# PIC32MX170F256D register map
Registers are 32-bit, access not given, reset 0x0 unless marked. A register's access mark holds for its fields unless they carry their own. Offsets are from the block's base; [hi:lo] are bit positions; {n}, {i} and the like mark numbered series; 'fields as' and 'values as' point back to an identical list.

## DMAC3 — DMAC3 peripheral
Base 0xBF8832A0
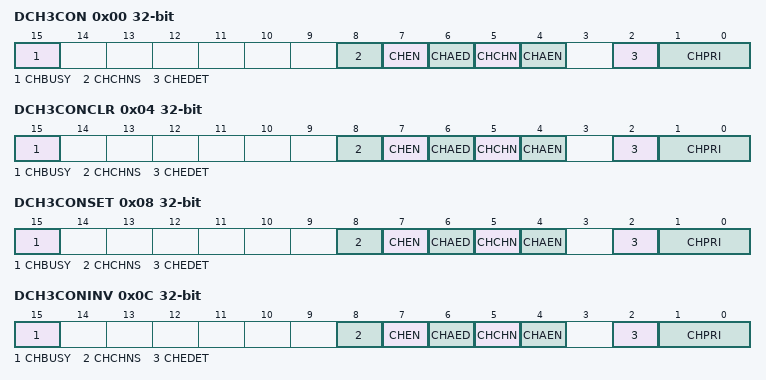
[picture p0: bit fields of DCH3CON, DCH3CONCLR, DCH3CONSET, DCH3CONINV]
0x00 DCH3CON
  [15] CHBUSY, [8] CHCHNS, [7] CHEN, [6] CHAED, [5] CHCHN, [4] CHAEN, [2] CHEDET, [1:0] CHPRI
0x04 DCH3CONCLR
  fields as DCH3CON
0x08 DCH3CONSET
  fields as DCH3CON
0x0C DCH3CONINV
  fields as DCH3CON
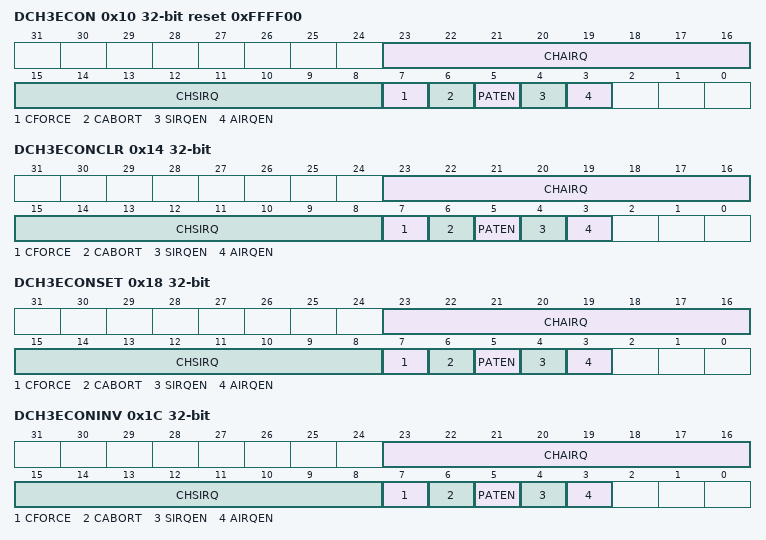
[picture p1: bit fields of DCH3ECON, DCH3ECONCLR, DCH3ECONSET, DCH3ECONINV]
0x10 DCH3ECON reset 0xFFFF00
  [23:16] CHAIRQ, [15:8] CHSIRQ, [7] CFORCE, [6] CABORT, [5] PATEN, [4] SIRQEN, [3] AIRQEN
0x14 DCH3ECONCLR
  fields as DCH3ECON
0x18 DCH3ECONSET
  fields as DCH3ECON
0x1C DCH3ECONINV
  fields as DCH3ECON
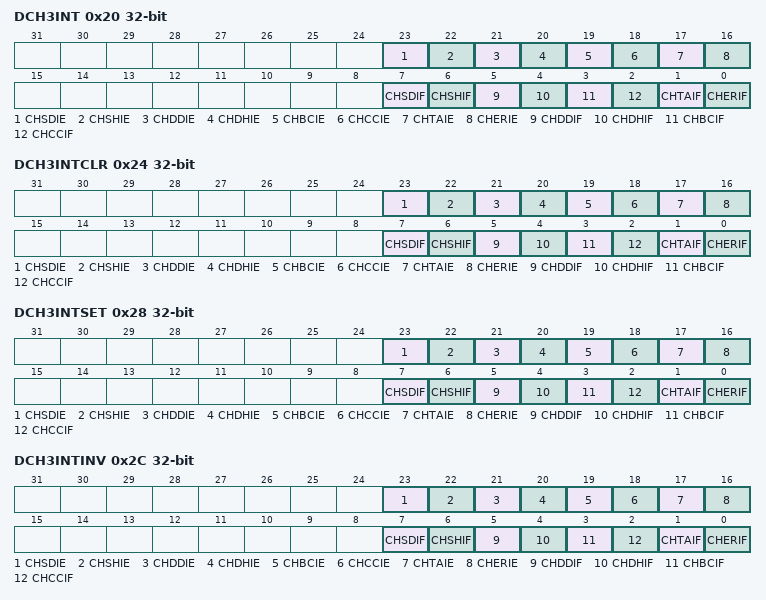
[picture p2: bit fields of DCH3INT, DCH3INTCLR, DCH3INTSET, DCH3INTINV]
0x20 DCH3INT
  [23] CHSDIE, [22] CHSHIE, [21] CHDDIE, [20] CHDHIE, [19] CHBCIE, [18] CHCCIE, [17] CHTAIE, [16] CHERIE, [7] CHSDIF, [6] CHSHIF, [5] CHDDIF, [4] CHDHIF, [3] CHBCIF, [2] CHCCIF, [1] CHTAIF, [0] CHERIF
0x24 DCH3INTCLR
  fields as DCH3INT
0x28 DCH3INTSET
  fields as DCH3INT
0x2C DCH3INTINV
  fields as DCH3INT
0x30 DCH3SSA
0x34 DCH3SSACLR
  [31:0] DCH3SSA
0x38 DCH3SSASET
  [31:0] DCH3SSA
0x3C DCH3SSAINV
  [31:0] DCH3SSA
0x40 DCH3DSA
0x44 DCH3DSACLR
  [31:0] DCH3DSA
0x48 DCH3DSASET
  [31:0] DCH3DSA
0x4C DCH3DSAINV
  [31:0] DCH3DSA
0x50 DCH3SSIZ
  [15:0] CHSSIZ
0x54 DCH3SSIZCLR
  [15:0] CHSSIZ
0x58 DCH3SSIZSET
  [15:0] CHSSIZ
0x5C DCH3SSIZINV
  [15:0] CHSSIZ
0x60 DCH3DSIZ
  [15:0] CHDSIZ
0x64 DCH3DSIZCLR
  [15:0] CHDSIZ
0x68 DCH3DSIZSET
  [15:0] CHDSIZ
0x6C DCH3DSIZINV
  [15:0] CHDSIZ
0x70 DCH3SPTR
  [15:0] CHSPTR
0x74 DCH3SPTRCLR
  [15:0] CHSPTR
0x78 DCH3SPTRSET
  [15:0] CHSPTR
0x7C DCH3SPTRINV
  [15:0] CHSPTR
0x80 DCH3DPTR
  [15:0] CHDPTR
0x84 DCH3DPTRCLR
  [15:0] CHDPTR
0x88 DCH3DPTRSET
  [15:0] CHDPTR
0x8C DCH3DPTRINV
  [15:0] CHDPTR
0x90 DCH3CSIZ
  [15:0] CHCSIZ
0x94 DCH3CSIZCLR
  [15:0] CHCSIZ
0x98 DCH3CSIZSET
  [15:0] CHCSIZ
0x9C DCH3CSIZINV
  [15:0] CHCSIZ
0xA0 DCH3CPTR
  [15:0] CHCPTR
0xA4 DCH3CPTRCLR
  [15:0] CHCPTR
0xA8 DCH3CPTRSET
  [15:0] CHCPTR
0xAC DCH3CPTRINV
  [15:0] CHCPTR
0xB0 DCH3DAT
  [7:0] DCHPDAT
0xB4 DCH3DATCLR
  [7:0] DCHPDAT
0xB8 DCH3DATSET
  [7:0] DCHPDAT
0xBC DCH3DATINV
  [7:0] DCHPDAT

## PORTA — PORTA peripheral
Base 0xBF886000
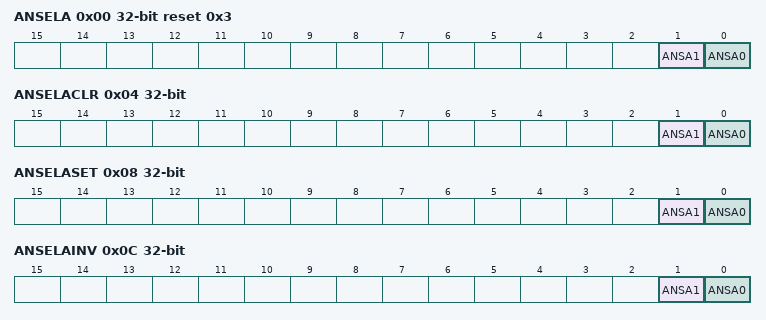
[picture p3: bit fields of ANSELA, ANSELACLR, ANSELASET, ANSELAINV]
0x00 ANSELA reset 0x3
  [1] ANSA1, [0] ANSA0
0x04 ANSELACLR
  [1] ANSA1, [0] ANSA0
0x08 ANSELASET
  [1] ANSA1, [0] ANSA0
0x0C ANSELAINV
  [1] ANSA1, [0] ANSA0
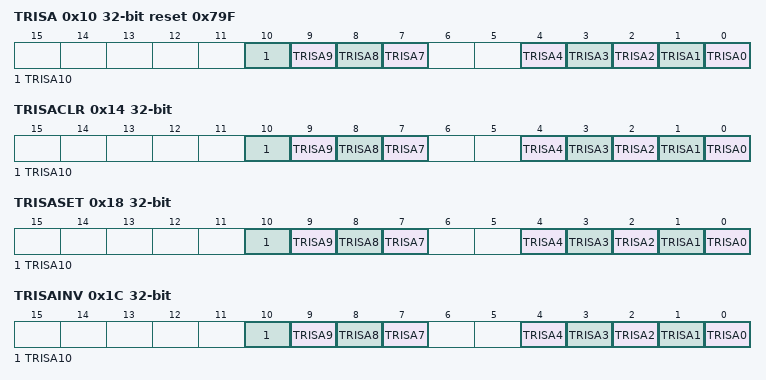
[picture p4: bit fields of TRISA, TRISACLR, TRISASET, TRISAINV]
0x10 TRISA reset 0x79F
  [n] TRISA{n} (n=7..10), [n] TRISA{n} (n=0..4)
0x14 TRISACLR
  [n] TRISA{n} (n=7..10), [n] TRISA{n} (n=0..4)
0x18 TRISASET
  [n] TRISA{n} (n=7..10), [n] TRISA{n} (n=0..4)
0x1C TRISAINV
  [n] TRISA{n} (n=7..10), [n] TRISA{n} (n=0..4)
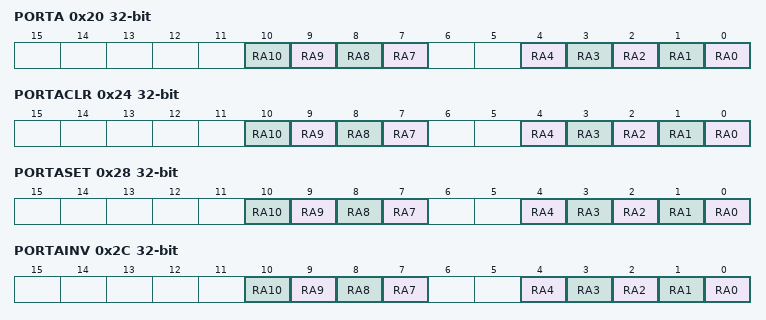
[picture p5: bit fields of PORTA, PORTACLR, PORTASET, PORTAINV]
0x20 PORTA
  [n] RA{n} (n=7..10), [n] RA{n} (n=0..4)
0x24 PORTACLR
  [n] RA{n} (n=7..10), [n] RA{n} (n=0..4)
0x28 PORTASET
  [n] RA{n} (n=7..10), [n] RA{n} (n=0..4)
0x2C PORTAINV
  [n] RA{n} (n=7..10), [n] RA{n} (n=0..4)
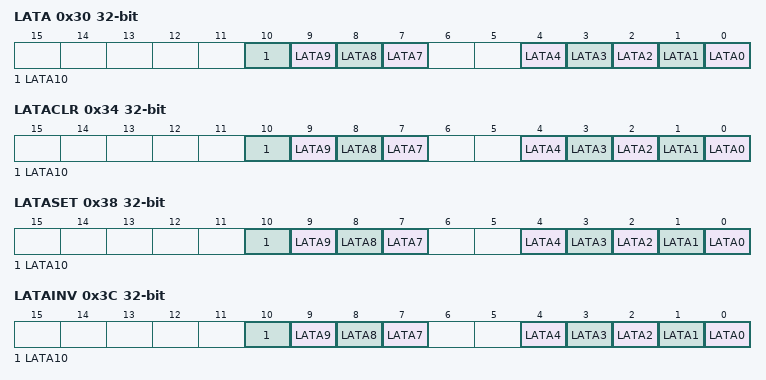
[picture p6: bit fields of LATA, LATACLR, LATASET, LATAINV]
0x30 LATA
  [n] LATA{n} (n=7..10), [n] LATA{n} (n=0..4)
0x34 LATACLR
  [n] LATA{n} (n=7..10), [n] LATA{n} (n=0..4)
0x38 LATASET
  [n] LATA{n} (n=7..10), [n] LATA{n} (n=0..4)
0x3C LATAINV
  [n] LATA{n} (n=7..10), [n] LATA{n} (n=0..4)
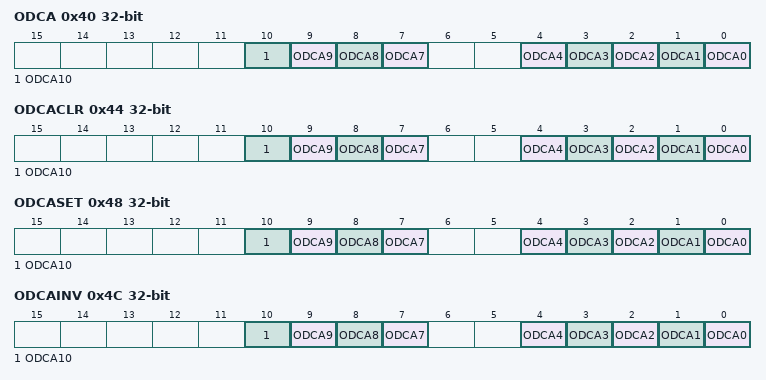
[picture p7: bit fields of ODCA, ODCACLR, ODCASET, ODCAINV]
0x40 ODCA
  [n] ODCA{n} (n=7..10), [n] ODCA{n} (n=0..4)
0x44 ODCACLR
  [n] ODCA{n} (n=7..10), [n] ODCA{n} (n=0..4)
0x48 ODCASET
  [n] ODCA{n} (n=7..10), [n] ODCA{n} (n=0..4)
0x4C ODCAINV
  [n] ODCA{n} (n=7..10), [n] ODCA{n} (n=0..4)
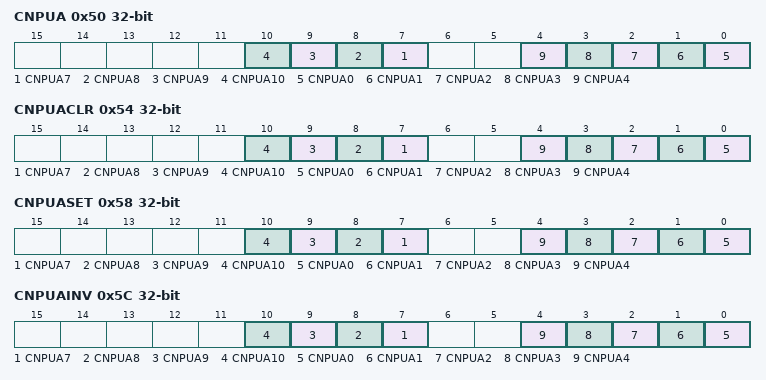
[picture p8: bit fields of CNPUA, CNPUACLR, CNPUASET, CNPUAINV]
0x50 CNPUA
  [n] CNPUA{n} (n=7..10), [n] CNPUA{n} (n=0..4)
0x54 CNPUACLR
  [n] CNPUA{n} (n=7..10), [n] CNPUA{n} (n=0..4)
0x58 CNPUASET
  [n] CNPUA{n} (n=7..10), [n] CNPUA{n} (n=0..4)
0x5C CNPUAINV
  [n] CNPUA{n} (n=7..10), [n] CNPUA{n} (n=0..4)
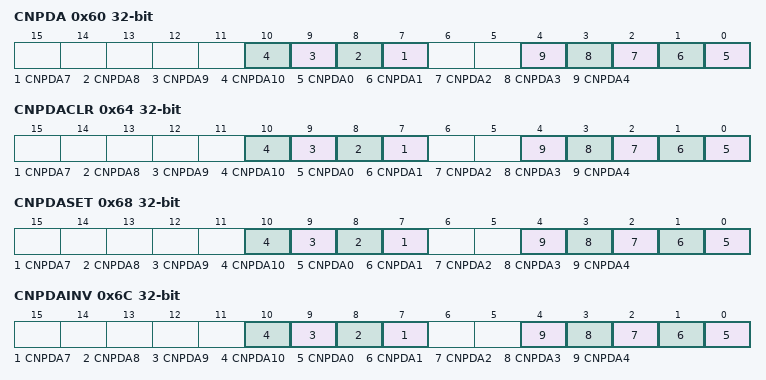
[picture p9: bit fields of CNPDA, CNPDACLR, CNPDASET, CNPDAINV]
0x60 CNPDA
  [n] CNPDA{n} (n=7..10), [n] CNPDA{n} (n=0..4)
0x64 CNPDACLR
  [n] CNPDA{n} (n=7..10), [n] CNPDA{n} (n=0..4)
0x68 CNPDASET
  [n] CNPDA{n} (n=7..10), [n] CNPDA{n} (n=0..4)
0x6C CNPDAINV
  [n] CNPDA{n} (n=7..10), [n] CNPDA{n} (n=0..4)
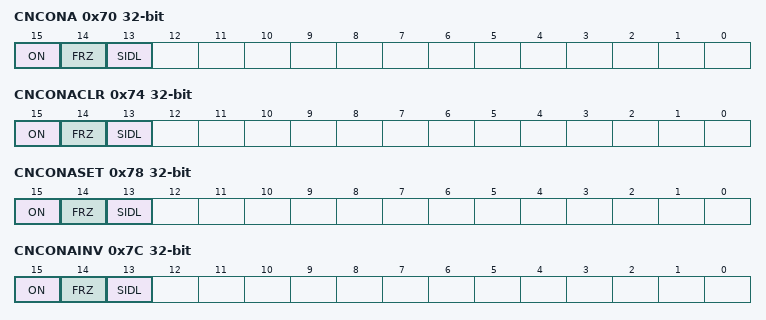
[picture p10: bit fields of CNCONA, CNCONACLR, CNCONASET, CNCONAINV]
0x70 CNCONA
  [15] ON, [14] FRZ, [13] SIDL
0x74 CNCONACLR
  [15] ON, [14] FRZ, [13] SIDL
0x78 CNCONASET
  [15] ON, [14] FRZ, [13] SIDL
0x7C CNCONAINV
  [15] ON, [14] FRZ, [13] SIDL
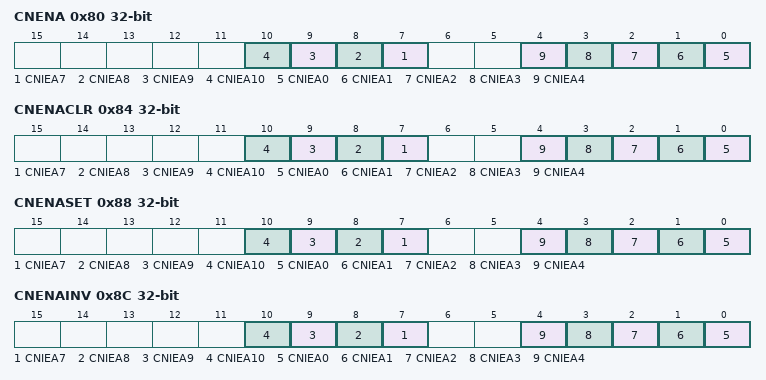
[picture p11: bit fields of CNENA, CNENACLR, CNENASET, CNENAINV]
0x80 CNENA
  [n] CNIEA{n} (n=7..10), [n] CNIEA{n} (n=0..4)
0x84 CNENACLR
  [n] CNIEA{n} (n=7..10), [n] CNIEA{n} (n=0..4)
0x88 CNENASET
  [n] CNIEA{n} (n=7..10), [n] CNIEA{n} (n=0..4)
0x8C CNENAINV
  [n] CNIEA{n} (n=7..10), [n] CNIEA{n} (n=0..4)
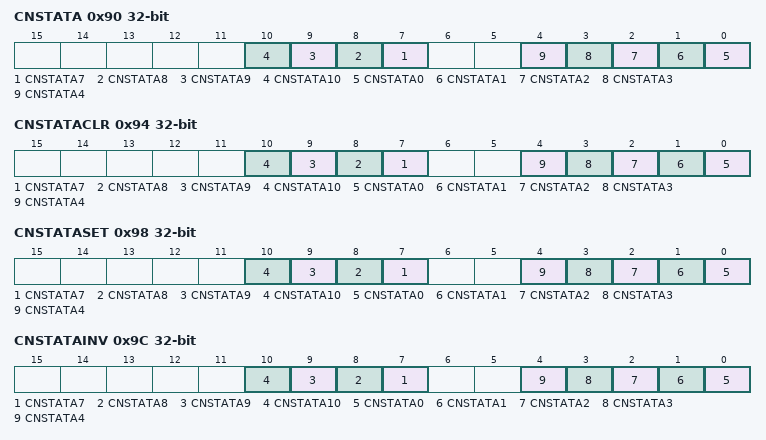
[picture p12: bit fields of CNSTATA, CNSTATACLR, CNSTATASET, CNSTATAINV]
0x90 CNSTATA
  [n] CNSTATA{n} (n=7..10), [n] CNSTATA{n} (n=0..4)
0x94 CNSTATACLR
  [n] CNSTATA{n} (n=7..10), [n] CNSTATA{n} (n=0..4)
0x98 CNSTATASET
  [n] CNSTATA{n} (n=7..10), [n] CNSTATA{n} (n=0..4)
0x9C CNSTATAINV
  [n] CNSTATA{n} (n=7..10), [n] CNSTATA{n} (n=0..4)

## PORTB — PORTB peripheral
Base 0xBF886100
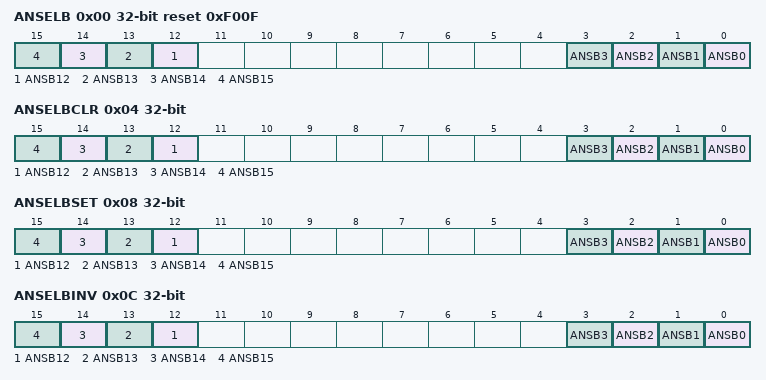
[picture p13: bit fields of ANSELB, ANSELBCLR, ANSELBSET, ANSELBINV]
0x00 ANSELB reset 0xF00F
  [n] ANSB{n} (n=12..15), [n] ANSB{n} (n=0..3)
0x04 ANSELBCLR
  [n] ANSB{n} (n=12..15), [n] ANSB{n} (n=0..3)
0x08 ANSELBSET
  [n] ANSB{n} (n=12..15), [n] ANSB{n} (n=0..3)
0x0C ANSELBINV
  [n] ANSB{n} (n=12..15), [n] ANSB{n} (n=0..3)
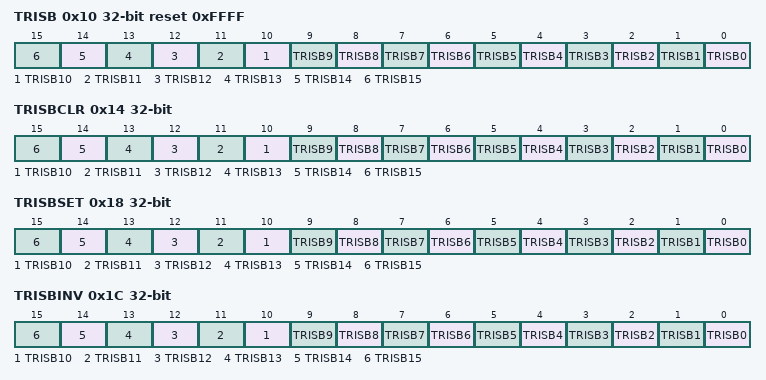
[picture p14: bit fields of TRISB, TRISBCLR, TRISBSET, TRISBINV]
0x10 TRISB reset 0xFFFF
  [n] TRISB{n} (n=0..15)
0x14 TRISBCLR
  [n] TRISB{n} (n=0..15)
0x18 TRISBSET
  [n] TRISB{n} (n=0..15)
0x1C TRISBINV
  [n] TRISB{n} (n=0..15)
0x20 PORTB
  [n] RB{n} (n=0..15)
0x24 PORTBCLR
  [n] RB{n} (n=0..15)
0x28 PORTBSET
  [n] RB{n} (n=0..15)
0x2C PORTBINV
  [n] RB{n} (n=0..15)
0x30 LATB
  [n] LATB{n} (n=0..15)
0x34 LATBCLR
  [n] LATB{n} (n=0..15)
0x38 LATBSET
  [n] LATB{n} (n=0..15)
0x3C LATBINV
  [n] LATB{n} (n=0..15)
0x40 ODCB
  [n] ODCB{n} (n=0..15)
0x44 ODCBCLR
  [n] ODCB{n} (n=0..15)
0x48 ODCBSET
  [n] ODCB{n} (n=0..15)
0x4C ODCBINV
  [n] ODCB{n} (n=0..15)
0x50 CNPUB
  [n] CNPUB{n} (n=0..15)
0x54 CNPUBCLR
  [n] CNPUB{n} (n=0..15)
0x58 CNPUBSET
  [n] CNPUB{n} (n=0..15)
0x5C CNPUBINV
  [n] CNPUB{n} (n=0..15)
0x60 CNPDB
  [n] CNPDB{n} (n=0..15)
0x64 CNPDBCLR
  [n] CNPDB{n} (n=0..15)
0x68 CNPDBSET
  [n] CNPDB{n} (n=0..15)
0x6C CNPDBINV
  [n] CNPDB{n} (n=0..15)
0x70 CNCONB
  [15] ON, [14] FRZ, [13] SIDL
0x74 CNCONBCLR
  [15] ON, [14] FRZ, [13] SIDL
0x78 CNCONBSET
  [15] ON, [14] FRZ, [13] SIDL
0x7C CNCONBINV
  [15] ON, [14] FRZ, [13] SIDL
0x80 CNENB
  [n] CNIEB{n} (n=0..15)
0x84 CNENBCLR
  [n] CNIEB{n} (n=0..15)
0x88 CNENBSET
  [n] CNIEB{n} (n=0..15)
0x8C CNENBINV
  [n] CNIEB{n} (n=0..15)
0x90 CNSTATB
  [n] CNSTATB{n} (n=0..15)
0x94 CNSTATBCLR
  [n] CNSTATB{n} (n=0..15)
0x98 CNSTATBSET
  [n] CNSTATB{n} (n=0..15)
0x9C CNSTATBINV
  [n] CNSTATB{n} (n=0..15)

## PORTC — PORTC peripheral
Base 0xBF886200
0x00 ANSELC reset 0xF
  [n] ANSC{n} (n=0..3)
0x04 ANSELCCLR
  [n] ANSC{n} (n=0..3)
0x08 ANSELCSET
  [n] ANSC{n} (n=0..3)
0x0C ANSELCINV
  [n] ANSC{n} (n=0..3)
0x10 TRISC reset 0x3FF
  [n] TRISC{n} (n=0..9)
0x14 TRISCCLR
  [n] TRISC{n} (n=0..9)
0x18 TRISCSET
  [n] TRISC{n} (n=0..9)
0x1C TRISCINV
  [n] TRISC{n} (n=0..9)
0x20 PORTC
  [n] RC{n} (n=0..9)
0x24 PORTCCLR
  [n] RC{n} (n=0..9)
0x28 PORTCSET
  [n] RC{n} (n=0..9)
0x2C PORTCINV
  [n] RC{n} (n=0..9)
0x30 LATC
  [n] LATC{n} (n=0..9)
0x34 LATCCLR
  [n] LATC{n} (n=0..9)
0x38 LATCSET
  [n] LATC{n} (n=0..9)
0x3C LATCINV
  [n] LATC{n} (n=0..9)
0x40 ODCC
  [n] ODCC{n} (n=0..9)
0x44 ODCCCLR
  [n] ODCC{n} (n=0..9)
0x48 ODCCSET
  [n] ODCC{n} (n=0..9)
0x4C ODCCINV
  [n] ODCC{n} (n=0..9)
0x50 CNPUC
  [n] CNPUC{n} (n=0..9)
0x54 CNPUCCLR
  [n] CNPUC{n} (n=0..9)
0x58 CNPUCSET
  [n] CNPUC{n} (n=0..9)
0x5C CNPUCINV
  [n] CNPUC{n} (n=0..9)
0x60 CNPDC
  [n] CNPDC{n} (n=0..9)
0x64 CNPDCCLR
  [n] CNPDC{n} (n=0..9)
0x68 CNPDCSET
  [n] CNPDC{n} (n=0..9)
0x6C CNPDCINV
  [n] CNPDC{n} (n=0..9)
0x70 CNCONC
  [15] ON, [14] FRZ, [13] SIDL
0x74 CNCONCCLR
  [15] ON, [14] FRZ, [13] SIDL
0x78 CNCONCSET
  [15] ON, [14] FRZ, [13] SIDL
0x7C CNCONCINV
  [15] ON, [14] FRZ, [13] SIDL
0x80 CNENC
  [n] CNIEC{n} (n=0..9)
0x84 CNENCCLR
  [n] CNIEC{n} (n=0..9)
0x88 CNENCSET
  [n] CNIEC{n} (n=0..9)
0x8C CNENCINV
  [n] CNIEC{n} (n=0..9)
0x90 CNSTATC
  [n] CNSTATC{n} (n=0..9)
0x94 CNSTATCCLR
  [n] CNSTATC{n} (n=0..9)
0x98 CNSTATCSET
  [n] CNSTATC{n} (n=0..9)
0x9C CNSTATCINV
  [n] CNSTATC{n} (n=0..9)
